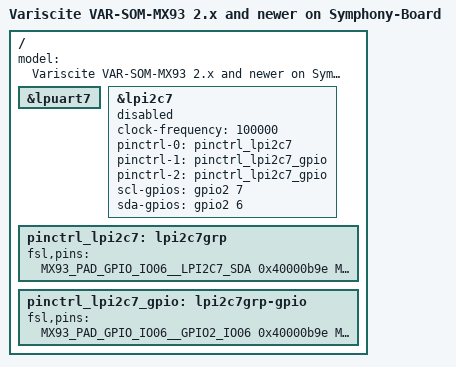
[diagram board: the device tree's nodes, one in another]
// SPDX-License-Identifier: (GPL-2.0+ OR MIT)
/*
 * Copyright 2023 Variscite Ltd.
 */

/dts-v1/;

#include "imx93-var-som.dtsi"
#include "imx93-var-som-symphony.dtsi"

/ {
	model = "Variscite VAR-SOM-MX93 2.x and newer on Symphony-Board";

	&lpuart7 {
		status = "ok";
	};


	&lpi2c7 {
		#address-cells = <1>;
		#size-cells = <0>;
		clock-frequency = <100000>;
		pinctrl-names = "default", "sleep", "gpio";
		pinctrl-0 = <&pinctrl_lpi2c7>;
		pinctrl-1 = <&pinctrl_lpi2c7_gpio>;
		pinctrl-2 = <&pinctrl_lpi2c7_gpio>;
		scl-gpios = <&gpio2 7 GPIO_ACTIVE_HIGH>;
		sda-gpios = <&gpio2 6 GPIO_ACTIVE_HIGH>;
		
		status = "disabled";
	};

	pinctrl_lpi2c7: lpi2c7grp {
		fsl,pins = <
			MX93_PAD_GPIO_IO06__LPI2C7_SDA			0x40000b9e
			MX93_PAD_GPIO_IO07__LPI2C7_SCL			0x40000b9e
		>;
	};

	pinctrl_lpi2c7_gpio: lpi2c7grp-gpio {
		fsl,pins = <
			MX93_PAD_GPIO_IO06__GPIO2_IO06			0x40000b9e
			MX93_PAD_GPIO_IO07__GPIO2_IO07			0x40000b9e
		>;
	};

};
